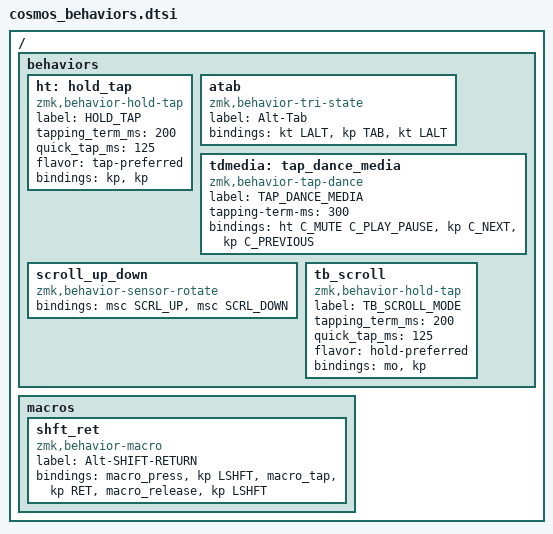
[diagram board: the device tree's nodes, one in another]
/*
 * Copyright (c) 2020 The ZMK Contributors
 *
 * SPDX-License-Identifier: MIT
 */

#include <dt-bindings/zmk/mouse.h>
#include <behaviors.dtsi>
#include <dt-bindings/zmk/keys.h>
#include <dt-bindings/zmk/bt.h>
#include <dt-bindings/zmk/outputs.h>
#include <behaviors/unicode.dtsi>
#include <dt-bindings/zmk/pointing.h>
#include <zmk-unicode/keys-extra.h>

/ {
	behaviors {
		ht: hold_tap {
			compatible = "zmk,behavior-hold-tap";
			label = "HOLD_TAP";
			#binding-cells = <2>;
			tapping_term_ms = <200>;
			quick_tap_ms = <125>;
			flavor = "tap-preferred";
			bindings = <&kp>, <&kp>;
		};
	};
};

/ {
	behaviors {
		atab: atab {
			compatible = "zmk,behavior-tri-state";
			label = "Alt-Tab";
			#binding-cells = <0>;
			bindings = <&kt LALT>, <&kp TAB>, <&kt LALT>;
			// ignored-key-positions = <2 3 4 5 6 7 8 9 10>;
			// ignored-layers = <5>;
		};
	};
};

/ {
	macros {
		shft_ret: shft_ret {
			compatible = "zmk,behavior-macro";
			label = "Alt-SHIFT-RETURN";
			#binding-cells = <0>;
			bindings
				= <&macro_press &kp LSHFT>
				, <&macro_tap &kp RET>
				, <&macro_release &kp LSHFT>
				;
		};
	};
};

/ {
	behaviors {
		tdmedia: tap_dance_media {
			compatible = "zmk,behavior-tap-dance";
			label = "TAP_DANCE_MEDIA";
			#binding-cells = <0>;
			tapping-term-ms = <300>;
			bindings =
				<&ht C_MUTE C_PLAY_PAUSE>, <&kp C_NEXT>, <&kp C_PREVIOUS>;
		};
	};
};

/ {
	behaviors {
		scroll_up_down: scroll_up_down {
			compatible = "zmk,behavior-sensor-rotate";
			#sensor-binding-cells = <0>;
			bindings = <&msc SCRL_UP>, <&msc SCRL_DOWN>;
//            tap-ms = <25>;
		};
	};
};

/ {
	behaviors {
		tb_scroll: tb_scroll {
			compatible = "zmk,behavior-hold-tap";
			label = "TB_SCROLL_MODE";
			#binding-cells = <2>;
			tapping_term_ms = <200>;
			quick_tap_ms = <125>;
			flavor = "hold-preferred";
			bindings = <&mo>, <&kp>;
		};
	};
};
